# SCRM register map
Vendor: Texas Instruments
Peripheral module from a debugger description file (folder omap5430_ES2_PUBLIC).
Registers are 32-bit, access per field, reset 0x0 unless marked. A register's access mark holds for its fields unless they carry their own. Offsets are as the file gives them; lines under a group give offsets from that group; [hi:lo] are bit positions; {n}, {i} and the like mark numbered series; 'fields as' and 'values as' point back to an identical list; <NAME> marks a mode.

## SCRM
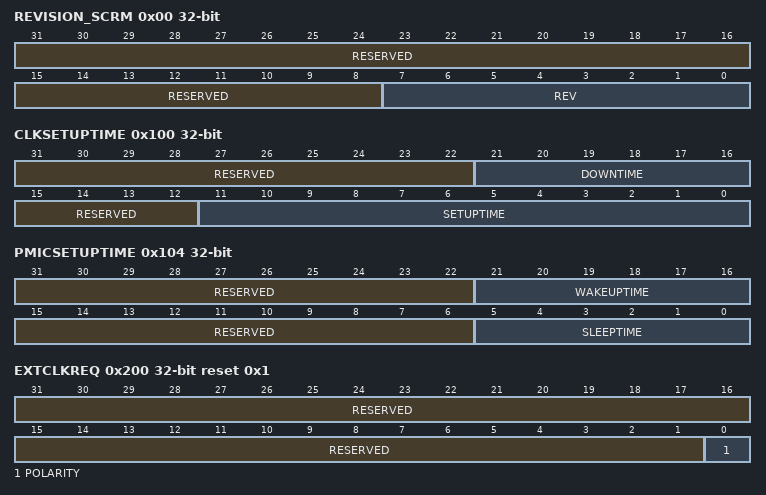
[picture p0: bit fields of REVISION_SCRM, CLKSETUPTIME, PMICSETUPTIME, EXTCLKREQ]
0x00 REVISION_SCRM ro (reset mask 0xFFFFFF00) — This register contains the IP revision code for the SCRM.
  [31:8] RESERVED — Reads returns 0.
  [7:0] REV — Revision Number
0x100 CLKSETUPTIME — This register holds the clock setup time counters of the system clock source supplier.
  [31:22] RESERVED ro — Reads returns 0.
  [21:16] DOWNTIME rw — Holds the number of 32 kHz clock cycles it takes to gate the clock source supplier.
  [15:12] RESERVED ro — Reads returns 0.
  [11:0] SETUPTIME rw — Holds the number of 32 kHz clock cycles it takes to stabilize the clock source supplier.
0x104 PMICSETUPTIME — This register holds the setup time counters for the sleep mode of the clock-source generator power supply (the power supply in external connected PMIC or LDO).
  [31:22] RESERVED ro — Reads returns 0.
  [21:16] WAKEUPTIME rw — Holds the number of 32 kHz clock cycles it takes to exit the clock-source generator power supply from sleep mode. SCRM starts Wakeup-time counter by activation of power request.
  [15:6] RESERVED ro — Reads returns 0.
  [5:0] SLEEPTIME rw — Holds the number of 32 kHz clock cycles it takes to enter the clock source generator power supply in sleep mode. SCRM activates Sleep-time counter by deactivation of power request.
0x200 EXTCLKREQ reset 0x1 — This register holds qualifiers for the external clock request.
  [31:1] RESERVED ro — Reads returns 0.
  [0] POLARITY rw — This bit defines the active level of the external clock request.
    0=ACT_LOW (The external clock request is active low.); 1=ACT_HIGH (The external clock request is active high.)
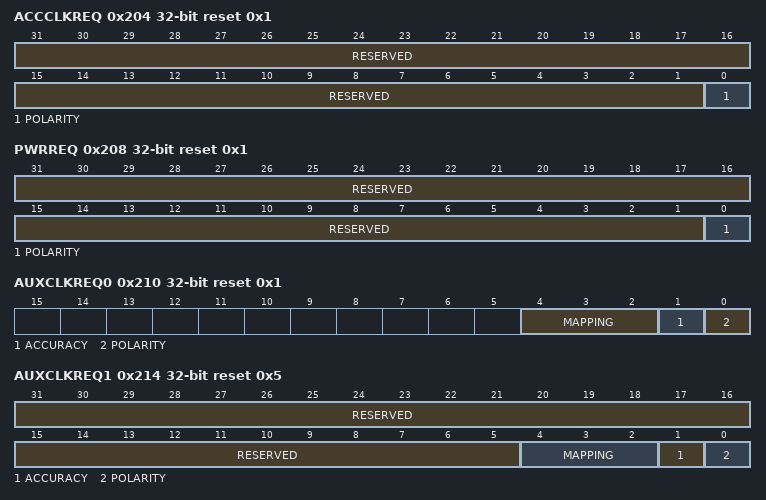
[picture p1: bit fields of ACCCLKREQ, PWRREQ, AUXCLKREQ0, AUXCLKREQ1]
0x204 ACCCLKREQ reset 0x1 — This register holds qualifiers for the accurate clock request.
  [31:1] RESERVED ro — Reads returns 0.
  [0] POLARITY rw — This bit defines the active level of the accurate clock request.
    0=ACT_LOW (The accurate clock request is active low.); 1=ACT_HIGH (The accurate clock request is active high.)
0x208 PWRREQ reset 0x1 — This register holds qualifiers for the external power request.
  [31:1] RESERVED ro — Reads returns 0.
  [0] POLARITY rw — This bit defines the active level of the external power request.
    0=ACT_LOW (The external power request is active low.); 1=ACT_HIGH (The external power request is active high.)
0x210 AUXCLKREQ0 reset 0x1 — This register holds qualifiers for the auxiliary clock request #0.
  [4:2] MAPPING rw — This field allows re-mapping the auxiliary clock request #0 on another auxiliary clock output than auxiliary clock #0.
    {v}=SEL{v} (The auxiliary clock request #0 is mapped on the auxiliary clock #{v}.) (v=0..3); 4=SEL4 (Reserved); 5=SEL5 (Reserved)
  [1] ACCURACY rw — This bit qualifies the auxiliary clock request #0 as an accurate clock request.
    0=NON_ACCU (An active auxiliary clock request #0 doesn't generate an accurate clock request.); 1=ACCU (An active auxiliary clock request #0 generates an accurate clock request.)
  [0] POLARITY rw — This bit defines the active level of the auxiliary clock request #0.
    0=ACT_LOW (The auxiliary clock request #0 is active low.); 1=ACT_HIGH (The auxiliary clock request #0 is active high.)
0x214 AUXCLKREQ1 reset 0x5 — This register holds qualifiers for the auxiliary clock request #1.
  [31:5] RESERVED ro — Reads returns 0.
  [4:2] MAPPING rw — This field allows re-mapping the auxiliary clock request #1 on another auxiliary clock output than auxiliary clock #1.
    {v}=SEL{v} (The auxiliary clock request #1 is mapped on the auxiliary clock #{v}.) (v=0..3); 4=SEL4 (Reserved); 5=SEL5 (Reserved)
  [1] ACCURACY rw — This bit qualifies the auxiliary clock request #1 as an accurate clock request.
    0=NON_ACCU (An active auxiliary clock request #1 doesn't generate an accurate clock request.); 1=ACCU (An active auxiliary clock request #1 generates an accurate clock request.)
  [0] POLARITY rw — This bit defines the active level of the auxiliary clock request #1.
    0=ACT_LOW (The auxiliary clock request #1 is active low.); 1=ACT_HIGH (The auxiliary clock request #1 is active high.)
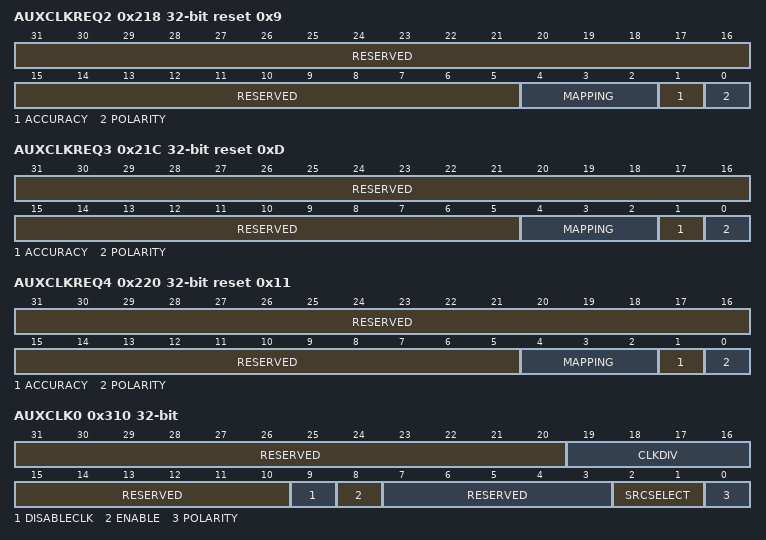
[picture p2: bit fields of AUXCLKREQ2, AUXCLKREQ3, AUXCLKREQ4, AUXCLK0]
0x218 AUXCLKREQ2 reset 0x9 — This register holds qualifiers for the auxiliary clock request #2.
  [31:5] RESERVED ro — Reads returns 0.
  [4:2] MAPPING rw — This field allows re-mapping the auxiliary clock request #2 on another auxiliary clock output than auxiliary clock #2.
    {v}=SEL{v} (The auxiliary clock request #2 is mapped on the auxiliary clock #{v}.) (v=0..3); 4=SEL4 (Reserved); 5=SEL5 (Reserved)
  [1] ACCURACY rw — This bit qualifies the auxiliary clock request #2 as an accurate clock request.
    0=NON_ACCU (An active auxiliary clock request #2 doesn't generate an accurate clock request.); 1=ACCU (An active auxiliary clock request #2 generates an accurate clock request.)
  [0] POLARITY rw — This bit defines the active level of the auxiliary clock request #2.
    0=ACT_LOW (The auxiliary clock request #2 is active low.); 1=ACT_HIGH (The auxiliary clock request #2 is active high.)
0x21C AUXCLKREQ3 reset 0xD — This register holds qualifiers for the auxiliary clock request #3.
  [31:5] RESERVED ro — Reads returns 0.
  [4:2] MAPPING rw — This field allows re-mapping the auxiliary clock request #3 on another auxiliary clock output than auxiliary clock #3.
    {v}=SEL{v} (The auxiliary clock request #3 is mapped on the auxiliary clock #{v}.) (v=0..3); 4=SEL4 (Reserved); 5=SEL5 (Reserved)
  [1] ACCURACY rw — This bit qualifies the auxiliary clock request #3 as an accurate clock request.
    0=NON_ACCU (An active auxiliary clock request #3 doesn't generate an accurate clock request.); 1=ACCU (An active auxiliary clock request #3 generates an accurate clock request.)
  [0] POLARITY rw — This bit defines the active level of the auxiliary clock request #3.
    0=ACT_LOW (The auxiliary clock request #3 is active low.); 1=ACT_HIGH (The auxiliary clock request #3 is active high.)
0x220 AUXCLKREQ4 reset 0x11 — This register holds qualifiers for the auxiliary clock request #4.
  [31:5] RESERVED ro — Reads returns 0.
  [4:2] MAPPING rw — This field allows re-mapping the auxiliary clock request #4 on another auxiliary clock output than auxiliary clock #4.
    {v}=SEL{v} (The auxiliary clock request #4 is mapped on the auxiliary clock #{v}.) (v=0..5)
  [1] ACCURACY rw — This bit qualifies the auxiliary clock request #4 as an accurate clock request.
    0=NON_ACCU (An active auxiliary clock request #4 doesn't generate an accurate clock request.); 1=ACCU (An active auxiliary clock request #4 generates an accurate clock request.)
  [0] POLARITY rw — This bit defines the active level of the auxiliary clock request #4.
    0=ACT_LOW (The auxiliary clock request #4 is active low.); 1=ACT_HIGH (The auxiliary clock request #4 is active high.)
0x310 AUXCLK0 — This register holds qualifiers for the auxiliary clock #0.
  [31:20] RESERVED ro — Reads returns 0.
  [19:16] CLKDIV rw — This field holds the divider value for the auxiliary clock #0.
    {v}=DIV_BY{v+1} (The auxiliary clock #0 is divided by {v+1}.) (v=0..15)
  [15:10] RESERVED ro — Reads returns 0.
  [9] DISABLECLK rw — This bit allows to gate the auxiliary clock #0 without condition. This is bit is intended to be used only when the SOC is not clock provider.
    0=EN_CLK (The auxiliary clock #0 is gated upon normal condition: auxiliary clock requests mapped on this path or ENABLE bit set.); 1=DIS_CLK (The auxiliary clock #0 is gated wihout conditon.)
  [8] ENABLE rw — This bit allows to request the auxiliary clock #0 by software.
    0=DIS (The auxiliary clock #0 is not requested by software.); 1=EN (The auxiliary clock #0 is requested by software.)
  [7:3] RESERVED ro — Reads returns 0.
  [2:1] SRCSELECT rw — This field allows selecting the clock source of the auxiliary clock #0.
    0=SEL0 (The clock source is the system clock (SYS_CLK).); 1=SEL1 (The clock source is the version from the DPLL_CORE.); 2=SEL2 (The clock source is the version from the DPLL_PER.); 3=SEL3 (Reserved)
  [0] POLARITY rw — This bit defines the output level when the auxiliary clock #0 is gated.
    0=GATED_LOW (The auxiliary clock #0 is gated low.); 1=GATED_HIGH (The auxiliary clock #0 is gated high.)
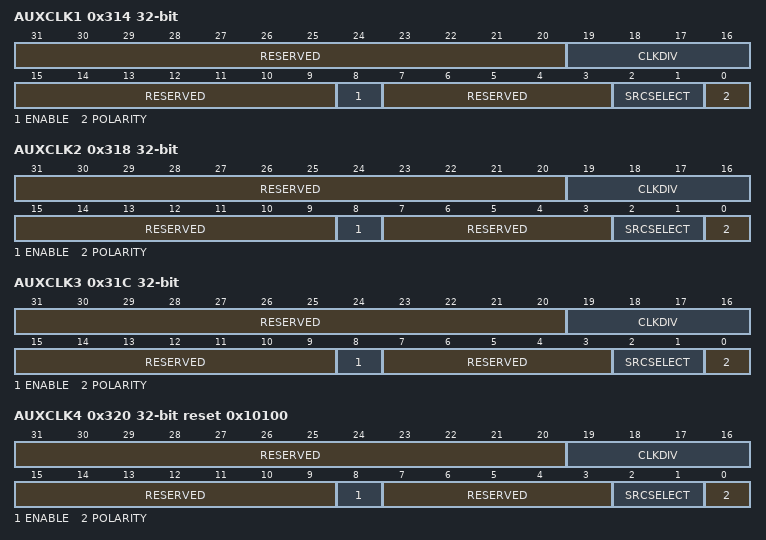
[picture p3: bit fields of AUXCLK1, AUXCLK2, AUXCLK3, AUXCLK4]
0x314 AUXCLK1 — This register holds qualifiers for the auxiliary clock #1.
  [31:20] RESERVED ro — Reads returns 0.
  [19:16] CLKDIV rw — This field holds the divider value for the auxiliary clock #1.
    {v}=DIV_BY{v+1} (The auxiliary clock #1 is divided by {v+1}.) (v=0..15)
  [15:9] RESERVED ro — Reads returns 0.
  [8] ENABLE rw — This bit allows to request the auxiliary clock #1 by software.
    0=DIS (The auxiliary clock #1 is not requested by software.); 1=EN (The auxiliary clock #1 is requested by software.)
  [7:3] RESERVED ro — Reads returns 0.
  [2:1] SRCSELECT rw — This field allows selecting the clock source of the auxiliary clock #1.
    0=SEL0 (The clock source is the system clock (SYS_CLK)); 1=SEL1 (The clock source is the version from the DPLL_CORE.); 2=SEL2 (The clock source is the version from the DPLL_PER.); 3=SEL3 (Reserved)
  [0] POLARITY rw — This bit defines the output level when the auxiliary clock #1 is gated.
    0=GATED_LOW (The auxiliary clock #1 is gated low.); 1=GATED_HIGH (The auxiliary clock #1 is gated high.)
0x318 AUXCLK2 — This register holds qualifiers for the auxiliary clock #2.
  [31:20] RESERVED ro — Reads returns 0.
  [19:16] CLKDIV rw — This field holds the divider value for the auxiliary clock #2.
    {v}=DIV_BY{v+1} (The auxiliary clock #2 is divided by {v+1}.) (v=0..15)
  [15:9] RESERVED ro — Reads returns 0.
  [8] ENABLE rw — This bit allows to request the auxiliary clock #2 by software.
    0=DIS (The auxiliary clock #2 is not requested by software.); 1=EN (The auxiliary clock #2 is requested by software.)
  [7:3] RESERVED ro — Reads returns 0.
  [2:1] SRCSELECT rw — This field allows selecting the clock source of the auxiliary clock #2.
    values as AUXCLK1.SRCSELECT
  [0] POLARITY rw — This bit defines the output level when the auxiliary clock #2 is gated.
    0=GATED_LOW (The auxiliary clock #2 is gated low.); 1=GATED_HIGH (The auxiliary clock #2 is gated high.)
0x31C AUXCLK3 — This register holds qualifiers for the auxiliary clock #3.
  [31:20] RESERVED ro — Reads returns 0.
  [19:16] CLKDIV rw — This field holds the divider value for the auxiliary clock #3.
    {v}=DIV_BY{v+1} (The auxiliary clock #3 is divided by {v+1}.) (v=0..15)
  [15:9] RESERVED ro — Reads returns 0.
  [8] ENABLE rw — This bit allows to request the auxiliary clock #3 by software.
    0=DIS (The auxiliary clock #3 is disabled by software.); 1=EN (The auxiliary clock #3 is requested by software.)
  [7:3] RESERVED ro — Reads returns 0.
  [2:1] SRCSELECT rw — This field allows selecting the clock source of the auxiliary clock #3.
    0=SEL0 (The clock source is the system clock.); 1=SEL1 (The clock source is the version from the DPLL_CORE.); 2=SEL2 (The clock source is the version from the DPLL_PER.); 3=SEL3 (Reserved)
  [0] POLARITY rw — This bit defines the output level when the auxiliary clock #3 is gated.
    0=GATED_LOW (The auxiliary clock #3 is gated low.); 1=GATED_HIGH (The auxiliary clock #3 is gated high.)
0x320 AUXCLK4 reset 0x10100 — This register holds qualifiers for the auxiliary clock #4.
  [31:20] RESERVED ro — Reads returns 0.
  [19:16] CLKDIV rw — This field holds the divider value for the auxiliary clock #4.
    {v}=DIV_BY{v+1} (The auxiliary clock #4 is divided by {v+1}.) (v=0..15)
  [15:9] RESERVED ro — Reads returns 0.
  [8] ENABLE rw — This bit allows to request the auxiliary clock #4 by software.
    0=DIS (The auxiliary clock #4 is disabled by software.); 1=EN (The auxiliary clock #4 is requested by software.)
  [7:3] RESERVED ro — Reads returns 0.
  [2:1] SRCSELECT rw — This field allows selecting the clock source of the auxiliary clock #4.
    0=SEL0 (The clock source is the system clock.); 1=SEL1 (The clock source is the version from the DPLL_CORE.); 2=SEL2 (The clock source is the version from the DPLL_PER.); 3=SEL3 (The clock source is the alternate clock)
  [0] POLARITY rw — This bit defines the output level when the auxiliary clock #4 is gated.
    0=GATED_LOW (The auxiliary clock #4 is gated low.); 1=GATED_HIGH (The auxiliary clock #4 is gated high.)
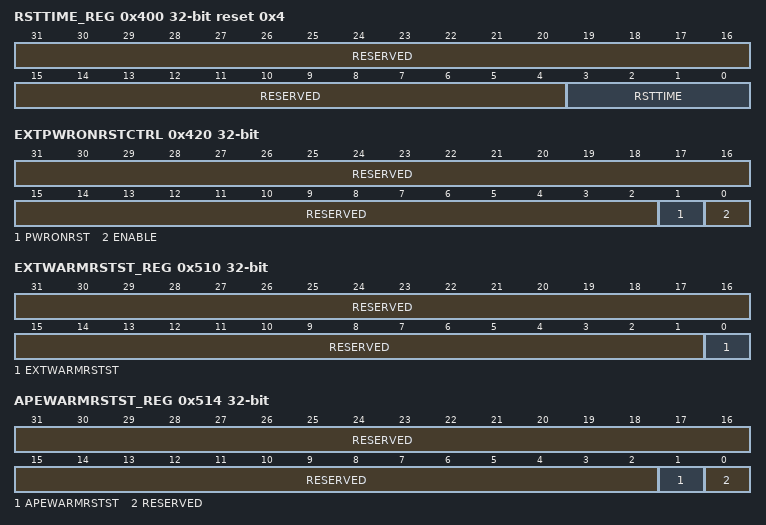
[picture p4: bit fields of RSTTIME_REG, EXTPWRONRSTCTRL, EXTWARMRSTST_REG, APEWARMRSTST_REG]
0x400 RSTTIME_REG reset 0x4 — This register holds the reset time counter which is used to extend the reset lines beyond the release of the pad reset.
  [31:4] RESERVED ro — Reads returns 0.
  [3:0] RSTTIME rw — Holds the number of 32 kHz clock cycles for which the reset duration is extended. Values 0,1 and 2 are not allowed. 0x0: Reserved. 0x1: Reserved. 0x2: Reserved.
0x420 EXTPWRONRSTCTRL access not given — This register allows the software to perform an external power-on reset.
  [31:2] RESERVED ro — Reads returns 0.
  [1] PWRONRST — This bit controls the assertion and the de-assertion of the external power-on reset. (access RW WSpecial)
    0=DEASSERT (De-asserts the external power-on reset.); 1=ASSERT (Asserts the external power-on reset.)
  [0] ENABLE — This bit must be set to 1 to allow the software to assert the external power-on reset. (access RW WSpecial)
    0=DISABLE (Prevents the software to assert the external power-on reset.); 1=ENABLE (Allows the software to assert the external power-on reset.)
0x510 EXTWARMRSTST_REG access not given — This register logs the source of warm reset output. Each bit is set upon release of the warm reset output and must be cleared by software.
  [31:1] RESERVED ro — Reads returns 0.
  [0] EXTWARMRSTST — This bit logs the external warm reset source. (access RW W1toClr)
    0=No_external_warm_reset_occurred; 1=An_external_warm_reset_occurred
0x514 APEWARMRSTST_REG access not given — This register logs the source of warm reset on the APE. Each bit is set upon release of the APE warm reset and must be cleared by software.
  [31:2] RESERVED ro — Reads returns 0.
  [1] APEWARMRSTST — This bit logs the APE warm reset source. (access RW W1toClr)
    0=No_APE_warm_reset_occurred; 1=An_APE_warm_reset_occurred
  [0] RESERVED ro — Reads returns 0.
